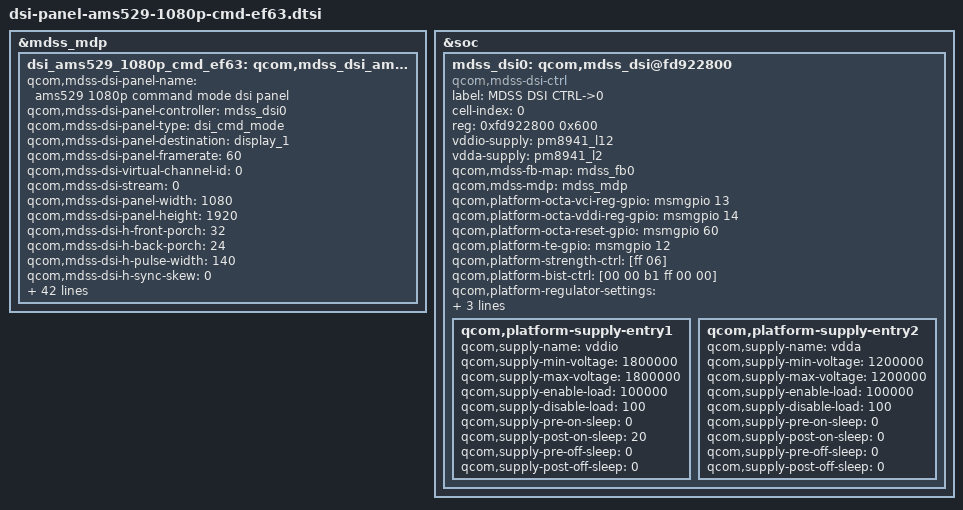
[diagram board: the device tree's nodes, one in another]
/* Copyright (c) 2013, The Linux Foundation. All rights reserved.
 *
 * This program is free software; you can redistribute it and/or modify
 * it under the terms of the GNU General Public License version 2 and
 * only version 2 as published by the Free Software Foundation.
 *
 * This program is distributed in the hope that it will be useful,
 * but WITHOUT ANY WARRANTY; without even the implied warranty of
 * MERCHANTABILITY or FITNESS FOR A PARTICULAR PURPOSE.  See the
 * GNU General Public License for more details.
 */

/*---------------------------------------------------------------------------
 * This file is autogenerated file using gcdb parser. Please do not edit it.
 * Update input XML file to add a new entry or update variable in this file
 * VERSION = "1.0"
 *---------------------------------------------------------------------------*/
&mdss_mdp {
	dsi_ams529_1080p_cmd_ef63: qcom,mdss_dsi_ams529_1080p_cmd_ef63 {
		qcom,mdss-dsi-panel-name = "ams529 1080p command mode dsi panel";
		qcom,mdss-dsi-panel-controller = <&mdss_dsi0>;
		qcom,mdss-dsi-panel-type = "dsi_cmd_mode";
		qcom,mdss-dsi-panel-destination = "display_1";
		qcom,mdss-dsi-panel-framerate = <60>;
/*		qcom,mdss-dsi-panel-clock-rate = <890000000>;*/
		qcom,mdss-dsi-virtual-channel-id = <0>;
		qcom,mdss-dsi-stream = <0>;
		qcom,mdss-dsi-panel-width = <1080>;
		qcom,mdss-dsi-panel-height = <1920>;
/*890Mbps 60hz*/	
		qcom,mdss-dsi-h-front-porch = <32>;
		qcom,mdss-dsi-h-back-porch = <24>;
		qcom,mdss-dsi-h-pulse-width = <140>;
		qcom,mdss-dsi-h-sync-skew = <0>;
		qcom,mdss-dsi-v-back-porch = <12>;
		qcom,mdss-dsi-v-front-porch = <4>;
		qcom,mdss-dsi-v-pulse-width = <2>;
		qcom,mdss-dsi-h-left-border = <0>;
		qcom,mdss-dsi-h-right-border = <0>;
		qcom,mdss-dsi-v-top-border = <0>;
		qcom,mdss-dsi-v-bottom-border = <0>;
		qcom,mdss-dsi-bpp = <24>;
		qcom,mdss-dsi-underflow-color = <0xff>;
		qcom,mdss-dsi-border-color = <0>;
		qcom,mdss-dsi-pixel-packing = <0>;
		qcom,mdss-dsi-pixel-alignment = <0>;
		qcom,mdss-dsi-on-command = [39 01 00 00 00 00 03 f0 5a 5a
					39 01 00 00 00 00 03 f1 5a 5a
					39 01 00 00 00 00 03 fc 5a 5a
					39 01 00 00 00 00 04 b9 05 01 27
					39 01 00 00 00 00 04 ba 85 33 06
					39 01 00 00 00 00 03 f4 02 00
					39 01 00 00 00 00 05 b8 19 04 00 00
					39 01 00 00 00 00 1a b1 08 86 15 46 31 32 13
                                            00 c0 18 06 ff 20 00
                                            00 00 00 00 00 00 00
                                            00 00 00 00
					39 01 00 00 00 00 05 bb b0 50 50 65
					39 01 00 00 00 00 02 b4 02
					39 01 00 00 00 00 0c b5 29 99 27 35 45 55 55 55
                                            4d 96 1d
					39 01 00 00 00 00 02 bf a0
					39 01 00 00 00 00 0a c0 13 D8 D8 0c 04 04 38
                                            07 80
					39 01 00 00 00 00 3f cb 56 1A 1D 14 C0 88 0F FF
                                            7F B7 7a f0 86 05 02 13
                                            08 00 00 A4 00 A4 0C 7A
                                            0C 7A 0C 7A 00 00 00 00
                                            00 00 00 00 29 68 30 00
                                            00 01 00 0c 0c 0c 02 00
                                            00 E4 8F F5 00 F5 70 F5
                                            70 00 2C 0A 2C 0A
					39 01 00 00 00 00 03 cc 55 0A
					39 01 00 00 00 00 05 ce 79 4E 04 00
					39 01 00 00 00 00 04 b6 4C 8B B8
					39 01 00 00 00 00 02 b0 05
					39 01 00 00 00 00 13 b6 00 00 00 00 00 00 00 00
                                            00 00 00 00 00 00 06 00
                                            06 80
                                   39 01 00 00 00 00 02 55 01	
					39 01 00 00 00 00 05 b8 14 04 00 00
					39 01 00 00 00 00 03 b6 4c 8b
					05 01 00 00 78 00 01 11					
					39 01 00 00 00 00 03 f1 a5 a5		
					39 01 00 00 00 00 03 fc a5 a5		
					05 01 00 00 00 00 01 29];
		qcom,mdss-dsi-off-command = [05 01 00 00 32 00 01 28
					05 01 00 00 78 00 01 10];
		qcom,mdss-dsi-on-command-state = "dsi_lp_mode";
		qcom,mdss-dsi-off-command-state = "dsi_hs_mode";
		qcom,mdss-dsi-h-sync-pulse = <1>;
		qcom,mdss-dsi-traffic-mode = "burst_mode";
		qcom,mdss-dsi-bllp-eof-power-mode;
		qcom,mdss-dsi-bllp-power-mode;
		qcom,mdss-dsi-lane-0-state;
		qcom,mdss-dsi-lane-1-state;
		qcom,mdss-dsi-lane-2-state;
		qcom,mdss-dsi-lane-3-state;
		qcom,mdss-dsi-te-pin-select = <1>;
		qcom,mdss-dsi-te-v-sync-rd-ptr-irq-line = <0x2c>;
		qcom,mdss-dsi-te-dcs-command = <1>;
		qcom,mdss-dsi-te-check-enable;
		qcom,mdss-dsi-te-using-te-pin;
/*890Mbps, 60hz*/
		qcom,mdss-dsi-panel-timings = [dd 43 3a 00 60 57 39 45 41 03 04 00];
		qcom,mdss-dsi-t-clk-post = <0x1e>;
		qcom,mdss-dsi-t-clk-pre = <0x36>;
		qcom,mdss-dsi-bl-min-level = <1>;
		qcom,mdss-dsi-bl-max-level = <31>;
		qcom,mdss-dsi-dma-trigger = "trigger_sw";
		qcom,mdss-dsi-mdp-trigger = "none";
		qcom,mdss-dsi-bl-pmic-control-type = "bl_ctrl_dcs";
		qcom,mdss-dsi-reset-sequence = <1 20>, <0 20>, <1 20>;
	};
};

&soc {
	mdss_dsi0: qcom,mdss_dsi@fd922800 {
		compatible = "qcom,mdss-dsi-ctrl";
		label = "MDSS DSI CTRL->0";
		cell-index = <0>;
		reg = <0xfd922800 0x600>;
		vddio-supply = <&pm8941_l12>;
		vdda-supply = <&pm8941_l2>;
		qcom,mdss-fb-map = <&mdss_fb0>;
		qcom,mdss-mdp = <&mdss_mdp>;
		qcom,platform-octa-vci-reg-gpio = <&msmgpio 13 0>;
		qcom,platform-octa-vddi-reg-gpio = <&msmgpio 14 0>;
		qcom,platform-octa-reset-gpio = <&msmgpio 60 0>;
		qcom,platform-te-gpio = <&msmgpio 12 0>;
		qcom,platform-strength-ctrl = [ff 06];
		qcom,platform-bist-ctrl = [00 00 b1 ff 00 00];
		qcom,platform-regulator-settings = [07 09 03 00 20 00 01];
		qcom,platform-lane-config = [00 00 00 00 00 00 00 01 97
			00 00 00 00 05 00 00 01 97
			00 00 00 00 0a 00 00 01 97
			00 00 00 00 0f 00 00 01 97
			00 c0 00 00 00 00 00 01 bb];
		qcom,platform-supply-entry1 {
				qcom,supply-name = "vddio";
				qcom,supply-min-voltage = <1800000>;
				qcom,supply-max-voltage = <1800000>;
				qcom,supply-enable-load = <100000>;
				qcom,supply-disable-load = <100>;
				qcom,supply-pre-on-sleep = <0>;
				qcom,supply-post-on-sleep = <20>;
				qcom,supply-pre-off-sleep = <0>;
				qcom,supply-post-off-sleep = <0>;
		};
		qcom,platform-supply-entry2 {
				qcom,supply-name = "vdda";
				qcom,supply-min-voltage = <1200000>;
				qcom,supply-max-voltage = <1200000>;
				qcom,supply-enable-load = <100000>;
				qcom,supply-disable-load = <100>;
				qcom,supply-pre-on-sleep = <0>;
				qcom,supply-post-on-sleep = <0>;
				qcom,supply-pre-off-sleep = <0>;
				qcom,supply-post-off-sleep = <0>;
		};
	};
};	
